# DA1470x register map
Vendor: Dialog; Series: DA1470x; File version: 1.2
CPU: CM33 r0p2, little endian, MPU, FPU, DSP, VTOR, 4 interrupt priority bits
Registers are 32-bit, read-write, reset 0x0 unless marked. A register's access mark holds for its fields unless they carry their own. Offsets are from the block's base; [hi:lo] are bit positions; 'fields as' and 'values as' point back to an identical list; <NAME> marks a mode.

## CRG_XTAL — CRG_XTAL registers
Base 0x50050400
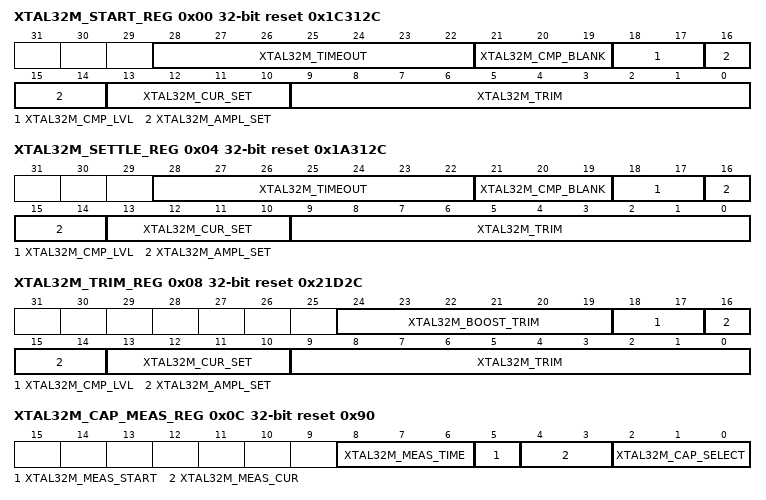
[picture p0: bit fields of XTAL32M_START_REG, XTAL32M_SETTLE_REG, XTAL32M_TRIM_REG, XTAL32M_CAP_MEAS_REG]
0x00 XTAL32M_START_REG reset 0x1C312C — Trim values for XTAL32M in START state of startup
  [28:22] XTAL32M_TIMEOUT — Timeout 0: disabled 1: 4us 2: 8us 63: 252us 64: 268us ... 127: 1260us
  [21:19] XTAL32M_CMP_BLANK — Blanking time for comparator output 0: disabled 1: 4us 2: 8us 3: 16us 4: 32us 5: 64us
  [18:17] XTAL32M_CMP_LVL — Comparator triplevel 0: 30% 1: 35% 2: 45% 3: 60%
  [16:14] XTAL32M_AMPL_SET — Amplitude Regulator input level setting (peak-peak) in START phase of startup 0: 300mV 1: 350mV .. 7: 900mV
  [13:10] XTAL32M_CUR_SET — Current setting (units of 16uA) in START phase of startup 0: OFF 1: 1x 2: 2x 3: 3x 4: 4x 5: 6x 6: 8x 7: 12x 8: 16x 9: 24x 10: 32x 11: 48x 12: 64x 13: 96x 14: 128x 15: 192x
  [9:0] XTAL32M_TRIM — Capacitance bank seting in START phase of startup CL = 3.5pF + 50fF/LSB
0x04 XTAL32M_SETTLE_REG reset 0x1A312C — Trim values for XTAL32M in SETTLE state of startup
  [28:22] XTAL32M_TIMEOUT — Timeout 0: disabled 1: 4us 2: 8us 63: 252us 64: 268us ... 127: 1260us
  [21:19] XTAL32M_CMP_BLANK — Blanking time for comparator output 0: disabled 1: 4us 2: 8us 3: 16us 4: 32us 5: 64us
  [18:17] XTAL32M_CMP_LVL — Comparator triplevel 0: 30% 1: 35% 2: 45% 3: 60%
  [16:14] XTAL32M_AMPL_SET — Amplitude Regulator input level setting (peak-peak) in SETTLE phase of startup 0: 300mV 1: 350mV .. 7: 900mV
  [13:10] XTAL32M_CUR_SET — Current setting (units of 16uA) in SETTLE phase of startup 0: OFF 1: 1x 2: 2x 3: 3x 4: 4x 5: 6x 6: 8x 7: 12x 8: 16x 9: 24x 10: 32x 11: 48x 12: 64x 13: 96x 14: 128x 15: 192x
  [9:0] XTAL32M_TRIM — Capacitance bank seting in SETLLE phase of startup CL = 3.5pF + 50fF/LSB
0x08 XTAL32M_TRIM_REG reset 0x21D2C — Trim values for XTAL32M in RUNNING state
  [24:19] XTAL32M_BOOST_TRIM — Boost trimming, set accordingly to shunt capacitance. Sensitivity: 125fF/LSB 0x0: Boost Disabled 1: 250fF 2: 375fF 3: 500fF; 4: 625fF; 62: 7.875pF 63: 8pF
  [18:17] XTAL32M_CMP_LVL — Comparator triplevel 0: 30% 1: 35% 2: 45% 3: 60%
  [16:14] XTAL32M_AMPL_SET — Amplitude Regulator input level setting (peak-peak) in running phase 0: 300mV 1: 350mV .. 7: 900mV
  [13:10] XTAL32M_CUR_SET — Current setting (units of 16uA) in running phase 0: OFF 1: 1x 2: 2x 3: 3x 4: 4x 5: 6x 6: 8x 7: 12x 8: 16x 9: 24x 10: 32x 11: 48x 12: 64x 13: 96x 14: 128x 15: 192x
  [9:0] XTAL32M_TRIM — Capacitance bank seting in running phase, use to trim the xtal32m output frequency CL = 3.5pF + 50fF/LSB
0x0C XTAL32M_CAP_MEAS_REG reset 0x90 — Capacitance measure circuit control
  [8:6] XTAL32M_MEAS_TIME — Select measurement time (in DIVN clock-cycles) 0: 32 1: 64 6: 2048 7: 4096
  [5] XTAL32M_MEAS_START — Starts capacitance measurement
  [4:3] XTAL32M_MEAS_CUR — Select measurement current (minimum required capacitance) 0: 100nA (0.44pF) 1: 500nA (2.22pF) 2: 1uA (4.44pF) 3: 5uA (22.2pF)
  [2:0] XTAL32M_CAP_SELECT — Select measured capacitance 0: disabled 1: hold capacitance 2: xtal_p 3: xtal_n 4: xtal_p + xtal_n 5: low reference on xtal_p 6: low reference on xtal_p
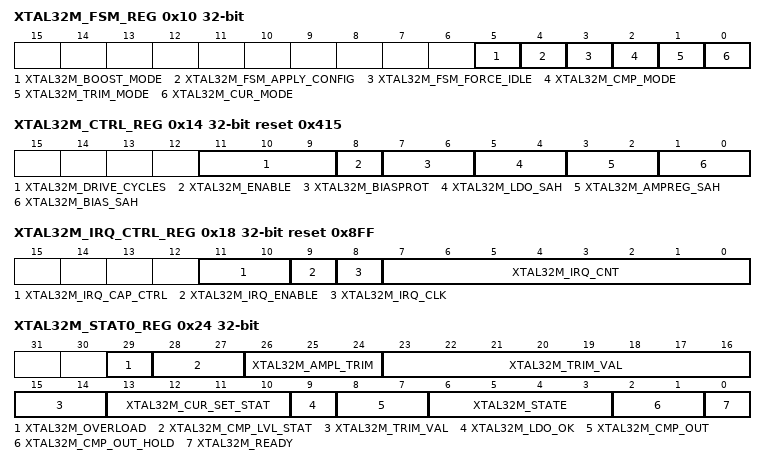
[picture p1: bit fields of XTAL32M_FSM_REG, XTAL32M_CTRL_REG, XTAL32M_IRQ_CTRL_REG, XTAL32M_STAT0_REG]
0x10 XTAL32M_FSM_REG — Startup state machine configuration
  [5] XTAL32M_BOOST_MODE — Boost mode configuration 0: Only allow BOOST mode in START state 1: Allow BOOST mode in SETTLE and START state
  [4] XTAL32M_FSM_APPLY_CONFIG — CUR_SET, AMPL_SET, CMP_LVL and TRIM from XTAL32M_TRIM_REG are 0: applied at next startup 1: immediately applied
  [3] XTAL32M_FSM_FORCE_IDLE — Forces FSM in IDLE state, allows for software control
  [2] XTAL32M_CMP_MODE — Use following comparator trim settings in SETTLE state: 0: XTAL32M_TRIM_REG.CMP_LVL 1: XTAL32M_SETTLE_REG.CMP_LVL
  [1] XTAL32M_TRIM_MODE — Use following trimsetting in the SETTLE state 0: XTAL32M_TRIM_REG.TRIM 1: XTAL32M_SETTLE_REG.TRIM
  [0] XTAL32M_CUR_MODE — Use the following current setting in the SETTLE state 0: XTAL32M_START_REG.CUR_SET 1: XTAL32M_SETTLE_REG.CUR_SET
0x14 XTAL32M_CTRL_REG reset 0x415 — Xtal32m control register
  [11:9] XTAL32M_DRIVE_CYCLES — Number of drive clock-cycles 0x0: Drive disabled 0x1: 4 0x2: 8 0x3: 16 0x4: 32 0x5: 64 0x6:128 0x7:256
  [8] XTAL32M_ENABLE — Enables xtal32m (testing purposes)
  [7:6] XTAL32M_BIASPROT — Bias startup circuit 0: enable during startup 1: always enabled 2: always disabled
  [5:4] XTAL32M_LDO_SAH — Controls amplitude regulator sample-and-hold 2'b00: set to HOLD when IRQ fires 2'b01: always TRACK 2'b1x: always HOLD
  [3:2] XTAL32M_AMPREG_SAH — Controls amplitude regulator sample-and-hold 2'b00: set to HOLD when IRQ fires 2'b01: always TRACK 2'b1x: always HOLD
  [1:0] XTAL32M_BIAS_SAH — Controls bias sample-and-hold 2'b00: set to HOLD when IRQ fires 2'b01: always TRACK 2'b1x: always HOLD
0x18 XTAL32M_IRQ_CTRL_REG reset 0x8FF — Xtal32m Interrupt control register
  [11:10] XTAL32M_IRQ_CAP_CTRL — The IRQ counter is captured in the XTAL32M_IRQ_STATUS_REG.IRQ_COUNT_CAP when leaving the following state 0: START 1: SETTLE 2: RUN
  [9] XTAL32M_IRQ_ENABLE — Enable xtal interrupt generation.
  [8] XTAL32M_IRQ_CLK — Clock divider for IRQ counter 0: 4us 1: 32us
  [7:0] XTAL32M_IRQ_CNT — IRQ counter start value.
0x24 XTAL32M_STAT0_REG — XTAL32M status register
  [29] XTAL32M_OVERLOAD ro — Indicates xtal is overloaded
  [28:27] XTAL32M_CMP_LVL_STAT ro — Current value for amplitude regulator comparator setting
  [26:24] XTAL32M_AMPL_TRIM ro — Current value for amplitude trim
  [23:14] XTAL32M_TRIM_VAL ro — Current value for oscillator trimming
  [13:10] XTAL32M_CUR_SET_STAT ro — Current value for cur_set
  [9] XTAL32M_LDO_OK ro — Indicates LDO voltage level is ok
  [8:7] XTAL32M_CMP_OUT ro — Amplitude regulator comparator output state
  [6:3] XTAL32M_STATE ro — State of xtal startup FSM 0x0: IDLE 0x1: WAIT_LDO 0x2: WAIT_BIAS 0x3: XTAL_DRIVE 0x4: START_BLANK 0x5: START 0x6: SETTLE_BLANK 0x7: SETTLE 0x8: RUN 0x9: CAP_TEST_IDLE 0xA: CAP_TEST_MEAS 0xB: CAP_TEST_END
  [2:1] XTAL32M_CMP_OUT_HOLD ro — Captured state of amplitude regulator comparators at IRQ fire.
  [0] XTAL32M_READY ro — Indicates xtal startup FSM has reached the RUNNIG state and is ready for use (sysclk)
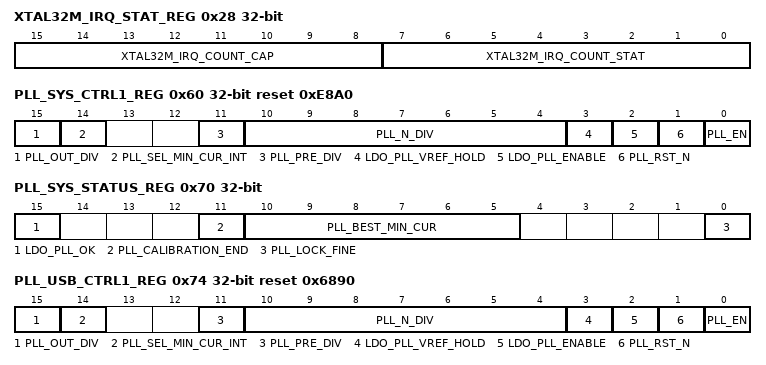
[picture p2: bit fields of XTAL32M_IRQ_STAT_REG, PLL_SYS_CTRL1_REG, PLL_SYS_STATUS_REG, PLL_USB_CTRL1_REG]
0x28 XTAL32M_IRQ_STAT_REG — XTAL32M IRQ status register
  [15:8] XTAL32M_IRQ_COUNT_CAP ro — Captured IRQ counter
  [7:0] XTAL32M_IRQ_COUNT_STAT ro — Current IRQ counter value
0x60 PLL_SYS_CTRL1_REG reset 0xE8A0 — System PLL control register 1.
  [15] PLL_OUT_DIV — 0: Output divider ON 1: Output divider OFF
  [14] PLL_SEL_MIN_CUR_INT — 0: VCO current read from min_current <5:0>, 1: VCO current is internally determined with a calibration algoritm.
  [11] PLL_PRE_DIV — PLL input divider (1: Indicates divide by 2).
  [10:4] PLL_N_DIV — PLL loop divider N (x means divide by x, 0 means divide by 1)
  [3] LDO_PLL_VREF_HOLD — 0: Indicates that the reference input is tracked, 1: Indicates that the reference input is sampled.
  [2] LDO_PLL_ENABLE — 0: LDO PLL off, 1: LDO PLL on.
  [1] PLL_RST_N — 0: PLL in Reset 1L PLL out of Reset
  [0] PLL_EN — 0: Power down 1: PLL on
0x64 PLL_SYS_CTRL2_REG reset 0xC80 — System PLL control register 2.
  [15] PLL_RECALIB — Recalibrate
0x68 PLL_SYS_CTRL3_REG reset 0x9870 — System PLL control register 3.
  [6:1] PLL_MIN_CURRENT — VCO current trimming.
0x70 PLL_SYS_STATUS_REG — System PLL status register.
  [15] LDO_PLL_OK ro — 1: Indicates that LDO PLL is in regulation.
  [11] PLL_CALIBRATION_END ro — Indicates that calibration has finished.
  [10:5] PLL_BEST_MIN_CUR ro — Calibrated VCO current.
  [0] PLL_LOCK_FINE ro — 1: PLL locked
0x74 PLL_USB_CTRL1_REG reset 0x6890 — USB PLL control register 1.
  fields as PLL_SYS_CTRL1_REG
0x78 PLL_USB_CTRL2_REG reset 0xC80 — USB PLL control register 2.
  [15] PLL_RECALIB — Recalibrate
0x7C PLL_USB_CTRL3_REG reset 0x9870 — USB PLL control register 3.
  [6:1] PLL_MIN_CURRENT — VCO current trimming.
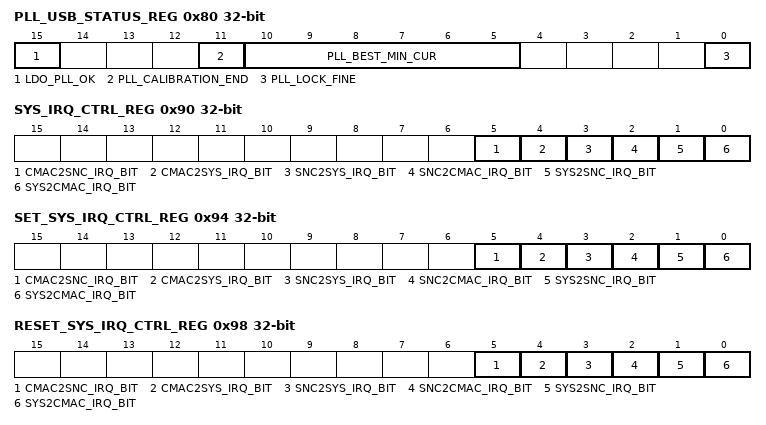
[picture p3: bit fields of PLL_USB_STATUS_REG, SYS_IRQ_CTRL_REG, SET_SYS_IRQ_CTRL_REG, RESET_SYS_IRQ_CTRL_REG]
0x80 PLL_USB_STATUS_REG — USB PLL status register.
  fields as PLL_SYS_STATUS_REG
0x90 SYS_IRQ_CTRL_REG — System IRQ control register
  [5] CMAC2SNC_IRQ_BIT, [4] CMAC2SYS_IRQ_BIT, [3] SNC2SYS_IRQ_BIT, [2] SNC2CMAC_IRQ_BIT, [1] SYS2SNC_IRQ_BIT, [0] SYS2CMAC_IRQ_BIT
0x94 SET_SYS_IRQ_CTRL_REG — System IRQ SET register
  fields as SYS_IRQ_CTRL_REG
0x98 RESET_SYS_IRQ_CTRL_REG — System IRQ RESET register
  fields as SYS_IRQ_CTRL_REG
